AUTOSAR XML (schema 00048)
package /ComponentTypes
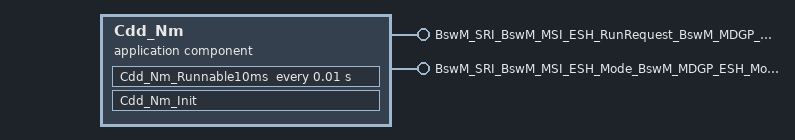
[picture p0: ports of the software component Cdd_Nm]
  application sw component type Cdd_Nm
    provide port BswM_SRI_BswM_MSI_ESH_RunRequest_BswM_MDGP_ESH_RunRequest: nonqueued-sender-com-spec=requestedMode, provided-interface=BswM_SRI_BswM_MSI_ESH_RunRequest_BswM_MDGP_ESH_RunRequest
    provide port BswM_SRI_BswM_MSI_ESH_Mode_BswM_MDGP_ESH_Mode: nonqueued-sender-com-spec=requestedMode, provided-interface=BswM_SRI_BswM_MSI_ESH_Mode_BswM_MDGP_ESH_Mode
    behavior Cdd_Nm_InternalBehavior
      timing event TMT_Cdd_Nm_Runnable10ms: start-on-event=Cdd_Nm_Runnable10ms, period=0.01
      init event Cdd_Nm_InitEvent: start-on-event=Cdd_Nm_Init
      runnable Cdd_Nm_Runnable10ms
        data-send-points:
          access SEND_BswM_SRI_BswM_MSI_ESH_Mode_BswM_MDGP_ESH_Mode_requestedMode: accessed-variable=BswM_SRI_BswM_MSI_ESH_Mode_BswM_MDGP_ESH_Mode.requestedMode
          access SEND_BswM_SRI_BswM_MSI_ESH_RunRequest_BswM_MDGP_ESH_RunRequest_requestedMode: accessed-variable=BswM_SRI_BswM_MSI_ESH_RunRequest_BswM_MDGP_ESH_RunRequest.requestedMode
      runnable Cdd_Nm_Init
  swc implementation Cdd_Nm_Implementation: behavior=Cdd_Nm_InternalBehavior
